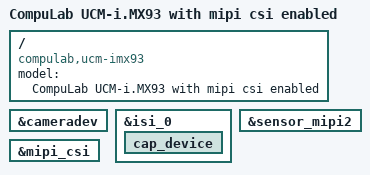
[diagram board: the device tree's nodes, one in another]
// SPDX-License-Identifier: (GPL-2.0+ OR MIT)
/*
 * Copyright 2023 CompuLab
 */

/dts-v1/;

#include "ucm-imx93.dtsi"
#include "ucm-imx93-mipi.dtsi"

/ {
	model = "CompuLab UCM-i.MX93 with mipi csi enabled";
	compatible = "compulab,ucm-imx93", "fsl,imx93";
};

&cameradev {
	status = "okay";
};

&isi_0 {
	status = "okay";

	cap_device {
		status = "okay";
	};
};

&sensor_mipi2 {
	status = "okay";
};

&mipi_csi {
        status = "okay";
};
